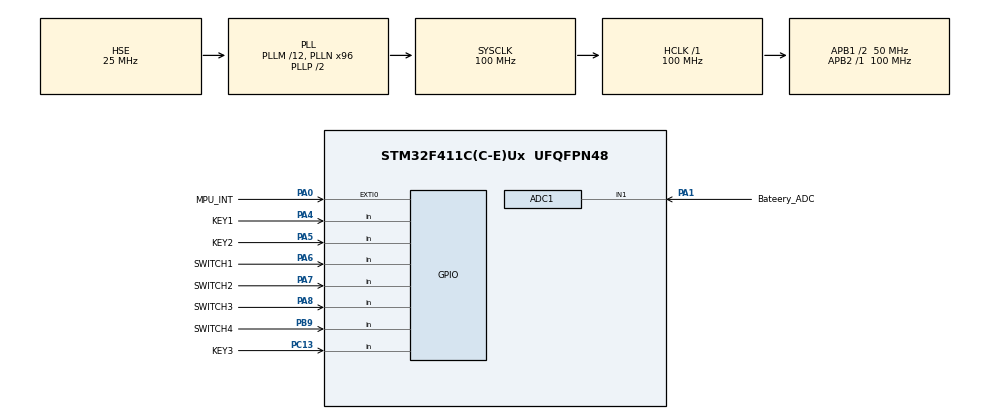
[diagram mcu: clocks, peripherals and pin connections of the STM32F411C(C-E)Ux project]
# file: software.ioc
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ADC1.Channel-0\#ChannelRegularConversion=ADC_CHANNEL_1
ADC1.NbrOfConversionFlag=1
ADC1.Rank-0\#ChannelRegularConversion=1
ADC1.SamplingTime-0\#ChannelRegularConversion=ADC_SAMPLETIME_144CYCLES
ADC1.master=1
Mcu.Family=STM32F4
Mcu.Name=STM32F411C(C-E)Ux
Mcu.Package=UFQFPN48
NVIC.PriorityGroup=NVIC_PRIORITYGROUP_4
PA0-WKUP.GPIO_Label=MPU_INT
PA0-WKUP.Signal=GPXTI0
PA1.GPIO_Label=Bateery_ADC
PA1.Signal=ADCx_IN1
PA10.GPIO_Label=GPS_RX
PA10.Signal=USART1_RX
PA2.GPIO_Label=ESP32_TX
PA2.Signal=USART2_TX
PA3.GPIO_Label=ESP32_RX
PA3.Signal=USART2_RX
PA4.GPIO_Label=KEY1
PA4.Signal=GPIO_Input
PA5.GPIO_Label=KEY2
PA5.Signal=GPIO_Input
PA6.GPIO_Label=SWITCH1
PA6.GPIO_Pull=GPIO_PULLUP
PA6.Signal=GPIO_Input
PA7.GPIO_Label=SWITCH2
PA7.GPIO_Pull=GPIO_PULLUP
PA7.Signal=GPIO_Input
PA8.GPIO_Label=SWITCH3
PA8.GPIO_Pull=GPIO_PULLUP
PA8.Signal=GPIO_Input
PA9.GPIO_Label=GPS_TX
PA9.Signal=USART1_TX
PB0.Signal=S_TIM3_CH3
PB1.Signal=S_TIM3_CH4
PB10.Signal=I2C2_SCL
PB3.Signal=I2C2_SDA
PB4.Signal=S_TIM3_CH1
PB5.Signal=S_TIM3_CH2
PB6.Signal=I2C1_SCL
PB7.Signal=I2C1_SDA
PB8.Signal=S_TIM4_CH3
PB9.GPIO_Label=SWITCH4
PB9.GPIO_Pull=GPIO_PULLUP
PB9.Signal=GPIO_Input
PC13-ANTI_TAMP.GPIO_Label=KEY3
PC13-ANTI_TAMP.Signal=GPIO_Input
PH0\ -\ OSC_IN.Mode=HSE-External-Oscillator
PH0\ -\ OSC_IN.Signal=RCC_OSC_IN
PH1\ -\ OSC_OUT.Mode=HSE-External-Oscillator
PH1\ -\ OSC_OUT.Signal=RCC_OSC_OUT
ProjectManager.HeapSize=0x200
ProjectManager.StackSize=0x400
ProjectManager.TargetToolchain=EWARM V8.50
RCC.48MHZClocksFreq_Value=50000000
RCC.AHBFreq_Value=100000000
RCC.APB1CLKDivider=RCC_HCLK_DIV2
RCC.APB1Freq_Value=50000000
RCC.APB1TimFreq_Value=100000000
RCC.APB2Freq_Value=100000000
RCC.APB2TimFreq_Value=100000000
RCC.CortexFreq_Value=100000000
RCC.HCLKFreq_Value=100000000
RCC.HSE_VALUE=25000000
RCC.HSI_VALUE=16000000
RCC.LSE_VALUE=32768
RCC.PLLM=12
RCC.PLLN=96
RCC.PLLSourceVirtual=RCC_PLLSOURCE_HSE
RCC.SYSCLKFreq_VALUE=100000000
RCC.SYSCLKSource=RCC_SYSCLKSOURCE_PLLCLK
RCC.VCOOutputFreq_Value=200000000
SH.ADCx_IN1.0=ADC1_IN1,IN1
SH.S_TIM3_CH1.0=TIM3_CH1
SH.S_TIM3_CH2.0=TIM3_CH2
SH.S_TIM3_CH3.0=TIM3_CH3
SH.S_TIM3_CH4.0=TIM3_CH4
SH.S_TIM4_CH3.0=TIM4_CH3
board=custom

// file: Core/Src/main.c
/* USER CODE BEGIN Header */
/**
  ******************************************************************************
  * @file           : main.c
  * @brief          : Main program body
  ******************************************************************************
  * @attention
  *
  * Copyright (c) 2026 STMicroelectronics.
  * All rights reserved.
  *
  * This software is licensed under terms that can be found in the LICENSE file
  * in the root directory of this software component.
  * If no LICENSE file comes with this software, it is provided AS-IS.
  *
  ******************************************************************************
  */
/* USER CODE END Header */
#include "main.h"

/* USER CODE BEGIN Includes */
#include "sensor_app.h"
#include "motor_app.h"
#include "ota_app.h"

/* USER CODE END Includes */

ADC_HandleTypeDef hadc1;

void SystemClock_Config(void);
static void MX_GPIO_Init(void);
static void MX_ADC1_Init(void);

int main(void)
{

  /* MCU Configuration--------------------------------------------------------*/

  /* Reset of all peripherals, Initializes the Flash interface and the Systick. */
  HAL_Init();

  /* Configure the system clock */
  SystemClock_Config();

  /* Initialize all configured peripherals */
  MX_GPIO_Init();
  MX_ADC1_Init();
  MotorApp_Init();
  /* USER CODE BEGIN 2 */
  SensorApp_Init();
  MotorApp_StartWatchdog();

  /* USER CODE END 2 */

  /* Infinite loop */
  while (1)
  {

    /* USER CODE BEGIN 3 */
    SensorApp_Poll();
    MotorApp_Poll();
    OtaApp_Poll();
  }
  /* USER CODE END 3 */
}

void SystemClock_Config(void)
{
  RCC_OscInitTypeDef RCC_OscInitStruct = {0};
  RCC_ClkInitTypeDef RCC_ClkInitStruct = {0};

  /** Configure the main internal regulator output voltage
  */
  __HAL_RCC_PWR_CLK_ENABLE();
  __HAL_PWR_VOLTAGESCALING_CONFIG(PWR_REGULATOR_VOLTAGE_SCALE1);

  /** Initializes the RCC Oscillators according to the specified parameters
  * in the RCC_OscInitTypeDef structure.
  */
  RCC_OscInitStruct.OscillatorType = RCC_OSCILLATORTYPE_HSE;
  RCC_OscInitStruct.HSEState = RCC_HSE_ON;
  RCC_OscInitStruct.PLL.PLLState = RCC_PLL_ON;
  RCC_OscInitStruct.PLL.PLLSource = RCC_PLLSOURCE_HSE;
  RCC_OscInitStruct.PLL.PLLM = 12;
  RCC_OscInitStruct.PLL.PLLN = 96;
  RCC_OscInitStruct.PLL.PLLP = RCC_PLLP_DIV2;
  RCC_OscInitStruct.PLL.PLLQ = 4;
  if (HAL_RCC_OscConfig(&RCC_OscInitStruct) != HAL_OK)
  {
    Error_Handler();
  }

  /** Initializes the CPU, AHB and APB buses clocks
  */
  RCC_ClkInitStruct.ClockType = RCC_CLOCKTYPE_HCLK|RCC_CLOCKTYPE_SYSCLK
                              |RCC_CLOCKTYPE_PCLK1|RCC_CLOCKTYPE_PCLK2;
  RCC_ClkInitStruct.SYSCLKSource = RCC_SYSCLKSOURCE_PLLCLK;
  RCC_ClkInitStruct.AHBCLKDivider = RCC_SYSCLK_DIV1;
  RCC_ClkInitStruct.APB1CLKDivider = RCC_HCLK_DIV2;
  RCC_ClkInitStruct.APB2CLKDivider = RCC_HCLK_DIV1;

  if (HAL_RCC_ClockConfig(&RCC_ClkInitStruct, FLASH_LATENCY_3) != HAL_OK)
  {
    Error_Handler();
  }
}

static void MX_ADC1_Init(void)
{

  ADC_ChannelConfTypeDef sConfig = {0};

  /** Configure the global features of the ADC (Clock, Resolution, Data Alignment and number of conversion)
  */
  hadc1.Instance = ADC1;
  hadc1.Init.ClockPrescaler = ADC_CLOCK_SYNC_PCLK_DIV4;
  hadc1.Init.Resolution = ADC_RESOLUTION_12B;
  hadc1.Init.ScanConvMode = DISABLE;
  hadc1.Init.ContinuousConvMode = DISABLE;
  hadc1.Init.DiscontinuousConvMode = DISABLE;
  hadc1.Init.ExternalTrigConvEdge = ADC_EXTERNALTRIGCONVEDGE_NONE;
  hadc1.Init.ExternalTrigConv = ADC_SOFTWARE_START;
  hadc1.Init.DataAlign = ADC_DATAALIGN_RIGHT;
  hadc1.Init.NbrOfConversion = 1;
  hadc1.Init.DMAContinuousRequests = DISABLE;
  hadc1.Init.EOCSelection = ADC_EOC_SINGLE_CONV;
  if (HAL_ADC_Init(&hadc1) != HAL_OK)
  {
    Error_Handler();
  }

  /** Configure for the selected ADC regular channel its corresponding rank in the sequencer and its sample time.
  */
  sConfig.Channel = ADC_CHANNEL_1;
  sConfig.Rank = 1;
  sConfig.SamplingTime = ADC_SAMPLETIME_144CYCLES;
  if (HAL_ADC_ConfigChannel(&hadc1, &sConfig) != HAL_OK)
  {
    Error_Handler();
  }

}

static void MX_GPIO_Init(void)
{
  GPIO_InitTypeDef GPIO_InitStruct = {0};

  /* GPIO Ports Clock Enable */
  __HAL_RCC_GPIOC_CLK_ENABLE();
  __HAL_RCC_GPIOH_CLK_ENABLE();
  __HAL_RCC_GPIOA_CLK_ENABLE();
  __HAL_RCC_GPIOB_CLK_ENABLE();

  /*Configure GPIO pin : MPU_INT_Pin */
  GPIO_InitStruct.Pin = MPU_INT_Pin;
  GPIO_InitStruct.Mode = GPIO_MODE_IT_RISING;
  GPIO_InitStruct.Pull = GPIO_NOPULL;
  HAL_GPIO_Init(MPU_INT_GPIO_Port, &GPIO_InitStruct);

  /*Configure GPIO pins : ESP32_TX_Pin ESP32_RX_Pin */
  GPIO_InitStruct.Pin = ESP32_TX_Pin|ESP32_RX_Pin;
  GPIO_InitStruct.Mode = GPIO_MODE_AF_PP;
  GPIO_InitStruct.Pull = GPIO_NOPULL;
  GPIO_InitStruct.Speed = GPIO_SPEED_FREQ_VERY_HIGH;
  GPIO_InitStruct.Alternate = GPIO_AF7_USART2;
  HAL_GPIO_Init(GPIOA, &GPIO_InitStruct);

  /*Configure GPIO pins : SWITCH1_Pin SWITCH2_Pin SWITCH3_Pin */
  GPIO_InitStruct.Pin = SWITCH1_Pin|SWITCH2_Pin|SWITCH3_Pin;
  GPIO_InitStruct.Mode = GPIO_MODE_INPUT;
  GPIO_InitStruct.Pull = GPIO_PULLUP;
  HAL_GPIO_Init(GPIOA, &GPIO_InitStruct);

  /*Configure GPIO pins : PB0 PB1 PB4 PB5 */
  GPIO_InitStruct.Pin = GPIO_PIN_0|GPIO_PIN_1|GPIO_PIN_4|GPIO_PIN_5;
  GPIO_InitStruct.Mode = GPIO_MODE_AF_PP;
  GPIO_InitStruct.Pull = GPIO_NOPULL;
  GPIO_InitStruct.Speed = GPIO_SPEED_FREQ_LOW;
  GPIO_InitStruct.Alternate = GPIO_AF2_TIM3;
  HAL_GPIO_Init(GPIOB, &GPIO_InitStruct);

  /*Configure GPIO pin : PB10 */
  GPIO_InitStruct.Pin = GPIO_PIN_10;
  GPIO_InitStruct.Mode = GPIO_MODE_AF_OD;
  GPIO_InitStruct.Pull = GPIO_NOPULL;
  GPIO_InitStruct.Speed = GPIO_SPEED_FREQ_VERY_HIGH;
  GPIO_InitStruct.Alternate = GPIO_AF4_I2C2;
  HAL_GPIO_Init(GPIOB, &GPIO_InitStruct);

  /*Configure GPIO pins : GPS_TX_Pin GPS_RX_Pin */
  GPIO_InitStruct.Pin = GPS_TX_Pin|GPS_RX_Pin;
  GPIO_InitStruct.Mode = GPIO_MODE_AF_PP;
  GPIO_InitStruct.Pull = GPIO_NOPULL;
  GPIO_InitStruct.Speed = GPIO_SPEED_FREQ_VERY_HIGH;
  GPIO_InitStruct.Alternate = GPIO_AF7_USART1;
  HAL_GPIO_Init(GPIOA, &GPIO_InitStruct);

  /*Configure GPIO pin : PB3 */
  GPIO_InitStruct.Pin = GPIO_PIN_3;
  GPIO_InitStruct.Mode = GPIO_MODE_AF_OD;
  GPIO_InitStruct.Pull = GPIO_NOPULL;
  GPIO_InitStruct.Speed = GPIO_SPEED_FREQ_VERY_HIGH;
  GPIO_InitStruct.Alternate = GPIO_AF9_I2C2;
  HAL_GPIO_Init(GPIOB, &GPIO_InitStruct);

  /*Configure GPIO pins : PB6 PB7 */
  GPIO_InitStruct.Pin = GPIO_PIN_6|GPIO_PIN_7;
  GPIO_InitStruct.Mode = GPIO_MODE_AF_OD;
  GPIO_InitStruct.Pull = GPIO_NOPULL;
  GPIO_InitStruct.Speed = GPIO_SPEED_FREQ_VERY_HIGH;
  GPIO_InitStruct.Alternate = GPIO_AF4_I2C1;
  HAL_GPIO_Init(GPIOB, &GPIO_InitStruct);

  /*Configure GPIO pin : PB8 */
  GPIO_InitStruct.Pin = GPIO_PIN_8;
  GPIO_InitStruct.Mode = GPIO_MODE_AF_PP;
  GPIO_InitStruct.Pull = GPIO_NOPULL;
  GPIO_InitStruct.Speed = GPIO_SPEED_FREQ_LOW;
  GPIO_InitStruct.Alternate = GPIO_AF2_TIM4;
  HAL_GPIO_Init(GPIOB, &GPIO_InitStruct);

  /*Configure GPIO pin : SWITCH4_Pin */
  GPIO_InitStruct.Pin = SWITCH4_Pin;
  GPIO_InitStruct.Mode = GPIO_MODE_INPUT;
  GPIO_InitStruct.Pull = GPIO_PULLUP;
  HAL_GPIO_Init(SWITCH4_GPIO_Port, &GPIO_InitStruct);

}

void Error_Handler(void)
{
  __disable_irq();
  while (1)
  {
  }
}
